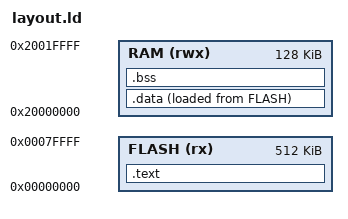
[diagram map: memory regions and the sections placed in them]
MEMORY
{
  FLASH (rx) : ORIGIN = 0x00000000, LENGTH = 512K
  RAM (rwx)  : ORIGIN = 0x20000000, LENGTH = 128K
}

SECTIONS
{
  .text : {
    KEEP(*(.vectors))
    *(.text*)
    *(.rodata*)    /* Read-only data like constants */
  } > FLASH

  /* This is where your 'memory storage' lives */
  .data : {
    *(.data*)
  } > RAM AT > FLASH

  .bss : {
    *(.bss*)
    *(COMMON)
  } > RAM
}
